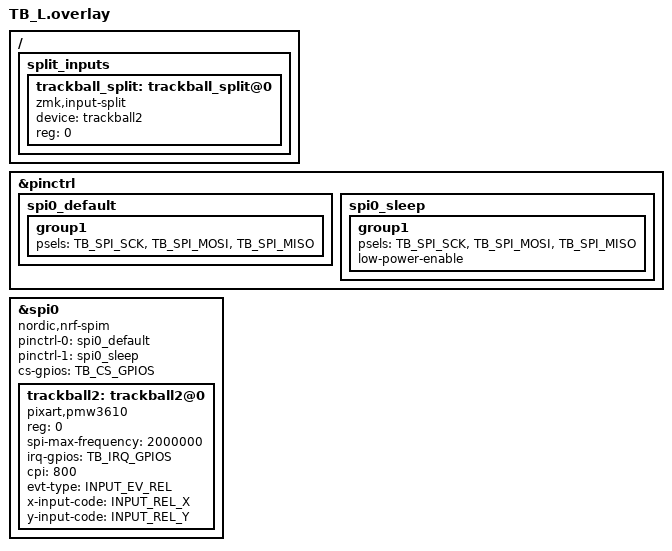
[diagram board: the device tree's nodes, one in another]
#include <input/processors.dtsi>
#include <dt-bindings/zmk/input_transform.h>
#include <zephyr/dt-bindings/input/input-event-codes.h>

/ {
    split_inputs {
        #address-cells = <1>;
        #size-cells = <0>;

        trackball_split: trackball_split@0 {
            compatible = "zmk,input-split";
            status = "okay";
            device = <&trackball2>;
            reg = <0>;
        };
    };
};

&pinctrl {
    spi0_default: spi0_default {
        group1 {
            psels = <TB_SPI_SCK>,
                    <TB_SPI_MOSI>,
                    <TB_SPI_MISO>;
        };
    };

    spi0_sleep: spi0_sleep {
        group1 {
            psels = <TB_SPI_SCK>,
                    <TB_SPI_MOSI>,
                    <TB_SPI_MISO>;
            low-power-enable;
        };
    };
};

&spi0 {
    status = "okay";
    compatible = "nordic,nrf-spim";
    pinctrl-0 = <&spi0_default>;
    pinctrl-1 = <&spi0_sleep>;
    pinctrl-names = "default", "sleep";
    cs-gpios = TB_CS_GPIOS;

    trackball2: trackball2@0 {
        status = "okay";
        compatible = "pixart,pmw3610";
        reg = <0>;
        spi-max-frequency = <2000000>;
        irq-gpios = TB_IRQ_GPIOS;
        cpi = <800>;
        evt-type = <INPUT_EV_REL>;
        x-input-code = <INPUT_REL_X>;
        y-input-code = <INPUT_REL_Y>;
    };
};
